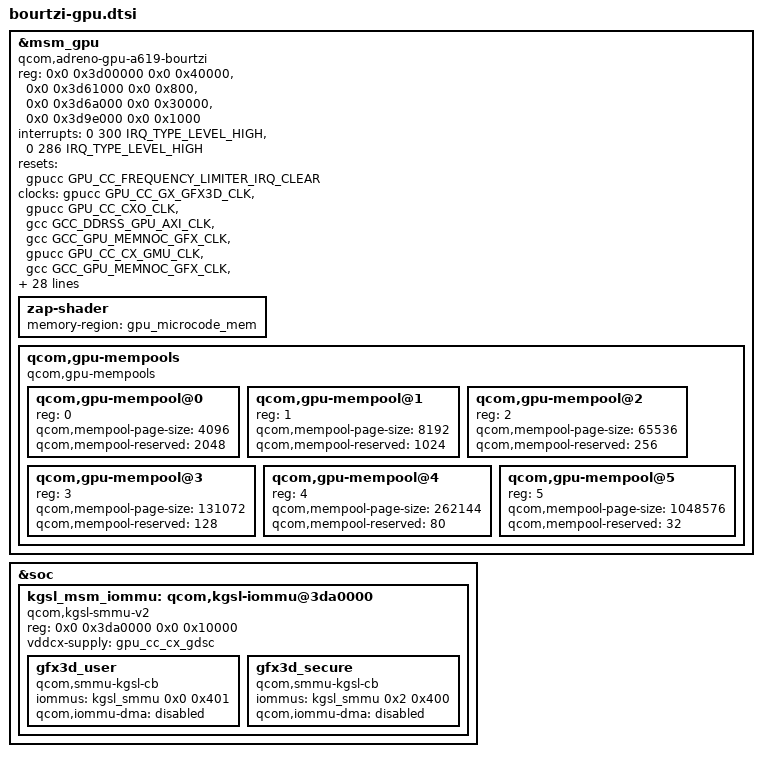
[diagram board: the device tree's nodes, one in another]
// SPDX-License-Identifier: BSD-3-Clause
/*
 * Copyright (c) Qualcomm Technologies, Inc. and/or its subsidiaries.
 */

#include <dt-bindings/regulator/qcom,rpmh-regulator-levels.h>
#define MHZ_TO_KBPS(mhz, w) ((mhz * 1000000 * w) / (1024))

&msm_gpu {
	compatible = "qcom,adreno-gpu-a619-bourtzi", "qcom,kgsl-3d0";
	status = "ok";
	reg = <0x0 0x3d00000 0x0 0x40000>, <0x0 0x3d61000 0x0 0x800>,
		<0x0 0x3d6a000 0x0 0x30000>, <0x0 0x3d9e000 0x0 0x1000>;
	reg-names = "kgsl_3d0_reg_memory", "cx_dbgc", "gmu_wrapper",
		"cx_misc";

	interrupts = <0 300 IRQ_TYPE_LEVEL_HIGH>, <0 286 IRQ_TYPE_LEVEL_HIGH>;
	interrupt-names = "kgsl_3d0_irq", "freq_limiter_irq";

	resets = <&gpucc GPU_CC_FREQUENCY_LIMITER_IRQ_CLEAR>;
	reset-names = "freq_limiter_irq_clear";

	clocks = <&gpucc GPU_CC_GX_GFX3D_CLK>,
		<&gpucc GPU_CC_CXO_CLK>,
		<&gcc GCC_DDRSS_GPU_AXI_CLK>,
		<&gcc GCC_GPU_MEMNOC_GFX_CLK>,
		<&gpucc GPU_CC_CX_GMU_CLK>,
		<&gcc GCC_GPU_MEMNOC_GFX_CLK>,
		<&gpucc GPU_CC_AHB_CLK>,
		<&gpucc GPU_CC_HLOS1_VOTE_GPU_SMMU_CLK>;

	clock-names = "core_clk",
		"rbbmtimer_clk",
		"iface_clk",
		"mem_clk",
		"gmu_clk",
		"gcc_gpu_memnoc_gfx",
		"gpu_cc_ahb",
		"gpu_cc_hlos1_vote_gpu_smmu";

	qcom,min-access-length = <32>;

	qcom,ubwc-mode = <2>;

	qcom,chipid = <0x06010903>;
	qcom,gpu-model = "Adreno629b";

	qcom,tzone-names = "gpuss-0", "gpuss-1";

	interconnects = <&gem_noc MASTER_GFX3D &mc_virt SLAVE_EBI1>;
	interconnect-names = "gpu_icc_path";

	qcom,bus-table-cnoc =
		<0>,   /* Off */
		<100>; /* On */

	qcom,bus-table-ddr7 =
		<MHZ_TO_KBPS(0, 4)>,    /* index=0              */
		<MHZ_TO_KBPS(200, 4)>,  /* index=1 (LOW SVS)    */
		<MHZ_TO_KBPS(547, 4)>,  /* index=2 (LOW SVS)    */
		<MHZ_TO_KBPS(768, 4)>,  /* index=3 (SVS)        */
		<MHZ_TO_KBPS(1017, 4)>, /* index=4 (SVS)        */
		<MHZ_TO_KBPS(1353, 4)>, /* index=5 (SVS_L1)     */
		<MHZ_TO_KBPS(1708, 4)>, /* index=6 (NOM)        */
		<MHZ_TO_KBPS(2092, 4)>; /* index=7 (TURBO)      */

	qcom,bus-table-ddr8 =
		<MHZ_TO_KBPS(0, 4)>,    /* index=0              */
		<MHZ_TO_KBPS(200, 4)>,  /* index=1 (LOW_SVS)    */
		<MHZ_TO_KBPS(547, 4)>,  /* index=2 (LOW_SVS)    */
		<MHZ_TO_KBPS(768, 4)>,  /* index=3 (SVS)        */
		<MHZ_TO_KBPS(1555, 4)>, /* index=4 (SVS)        */
		<MHZ_TO_KBPS(1708, 4)>, /* index=5 (SVS_L1)     */
		<MHZ_TO_KBPS(2092, 4)>, /* index=6 (NOM)        */
		<MHZ_TO_KBPS(2736, 4)>, /* index=7 (TURBO)      */
		<MHZ_TO_KBPS(3197, 4)>; /* index=8 (TURBO)      */

	/* GDSC regulator names */
	regulator-names = "vddcx", "vdd";

	/* GDSC oxili regulators */
	vddcx-supply = <&gpu_cc_cx_gdsc>;
	vdd-supply = <&gpu_cc_gx_gdsc>;
	vdd-parent-supply = <&VDD_GFX_LEVEL>;
	vdd-parent-min-corner = <RPMH_REGULATOR_LEVEL_RETENTION>;

	nvmem-cells = <&gpu_speed_bin>;
	nvmem-cell-names = "speed_bin";

	zap-shader {
		memory-region = <&gpu_microcode_mem>;
	};

	qcom,gpu-mempools {
		#address-cells = <1>;
		#size-cells = <0>;
		compatible = "qcom,gpu-mempools";

		/* 4K Page Pool configuration */
		qcom,gpu-mempool@0 {
			reg = <0>;
			qcom,mempool-page-size = <4096>;
			qcom,mempool-reserved = <2048>;
		};
		/* 8K Page Pool configuration */
		qcom,gpu-mempool@1 {
			reg = <1>;
			qcom,mempool-page-size = <8192>;
			qcom,mempool-reserved = <1024>;
		};
		/* 64K Page Pool configuration */
		qcom,gpu-mempool@2 {
			reg = <2>;
			qcom,mempool-page-size = <65536>;
			qcom,mempool-reserved = <256>;
		};
		/* 128K Page Pool configuration */
		qcom,gpu-mempool@3 {
			reg = <3>;
			qcom,mempool-page-size = <131072>;
			qcom,mempool-reserved = <128>;
		};
		/* 256K Page Pool configuration */
		qcom,gpu-mempool@4 {
			reg = <4>;
			qcom,mempool-page-size = <262144>;
			qcom,mempool-reserved = <80>;
		};
		/* 1M Page Pool configuration */
		qcom,gpu-mempool@5 {
			reg = <5>;
			qcom,mempool-page-size = <1048576>;
			qcom,mempool-reserved = <32>;
		};
	};
};

&soc {
	kgsl_msm_iommu: qcom,kgsl-iommu@3da0000 {
		compatible = "qcom,kgsl-smmu-v2";
		reg = <0x0 0x3da0000 0x0 0x10000>;

		vddcx-supply = <&gpu_cc_cx_gdsc>;

		gfx3d_user: gfx3d_user {
			compatible = "qcom,smmu-kgsl-cb";
			iommus = <&kgsl_smmu 0x0 0x401>;
			qcom,iommu-dma = "disabled";
		};

		gfx3d_secure: gfx3d_secure {
			compatible = "qcom,smmu-kgsl-cb";
			iommus = <&kgsl_smmu 0x2 0x400>;
			qcom,iommu-dma = "disabled";
		};
	};
};
